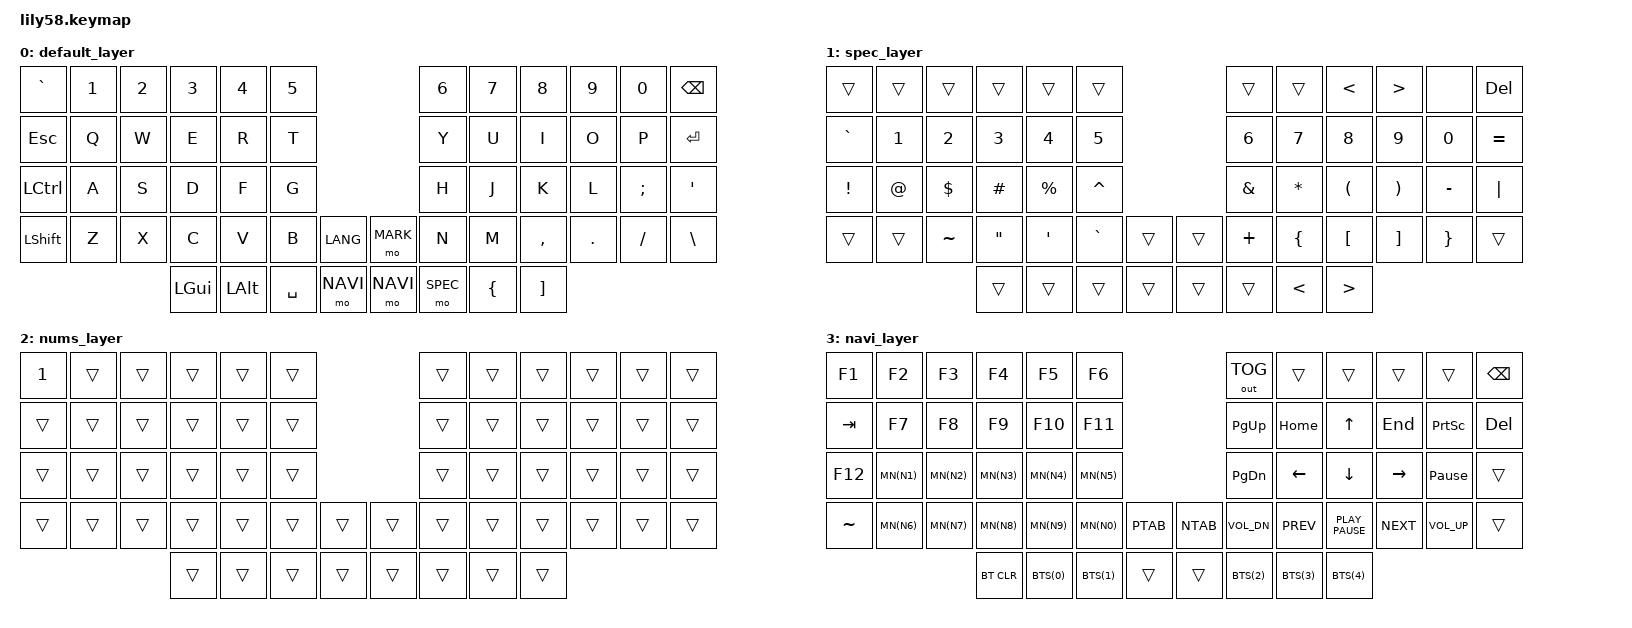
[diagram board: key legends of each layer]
/*
 * Copyright (c) 2020 The ZMK Contributors
 *
 * SPDX-License-Identifier: MIT
 */

#include <behaviors.dtsi>
#include <dt-bindings/zmk/keys.h>
#include <dt-bindings/zmk/bt.h>
#include <dt-bindings/zmk/outputs.h>
#include <dt-bindings/zmk/ext_power.h>

#define SPEC 1
#define NUMS 2
#define NAVI 3
#define MARK LC(SPACE)
#define BTS(n) &bt BT_SEL n
#define LANG CLCK
#define MN(n) &kp LG n
#define NTAB LC(TAB)
#define PTAB LC(LS(TAB))

/ {
	keymap {
		compatible = "zmk,keymap";

		default_layer {
// ---------------------------------------------------------------------------------------------------------
// |   `    |  1  |  2  |  3  |  4  |   5   |                    |   6   |   7   |  8  |  9  |  0  | BKSPC |
// |  ESC   |  Q  |  W  |  E  |  R  |   T   |                    |   Y   |   U   |  I  |  O  |  P  | ENTER |
// |  CTRL  |  A  |  S  |  D  |  F  |   G   |                    |   H   |   J   |  K  |  L  |  ;  |   '   |
// |  SHIFT |  Z  |  X  |  C  |  V  |   B   |  LANG  |  | MARK   |   N   |   M   |  ,  |  .  |  /  |   \   |
//                      | GUI | ALT |  SPC  |  NAVI  |  | NAVI   |  SPEC |   [   |  ]  |         
			bindings = <
&kp GRAVE &kp N1 &kp N2 &kp N3   &kp N4   &kp N5                          &kp N6    &kp N7    &kp N8    &kp N9  &kp N0    &kp BSPC
&kp ESC   &kp Q  &kp W  &kp E    &kp R    &kp T                           &kp Y     &kp U     &kp I     &kp O   &kp P     &kp ENTER
&kp LCTRL &kp A  &kp S  &kp D    &kp F    &kp G                           &kp H     &kp J     &kp K     &kp L   &kp SEMI  &kp SQT
&kp LSHFT &kp Z  &kp X  &kp C    &kp V    &kp B     &kp LANG   &mo MARK   &kp N     &kp M     &kp COMMA &kp DOT &kp SLASH &kp BACKSLASH
                        &kp LGUI &kp LALT &kp SPACE &mo NAVI   &mo NAVI   &mo SPEC  &kp LBRC  &kp RBKT
			>;
		};

		spec_layer {
// ----------------------------------------------------------------------------------------------------
// |     |     |     |     |     |       |                    |       |       |  <  |  >  |     | DEL |
// |  `  |  1  |  2  |  3  |  4  |   5   |                    |   6   |   7   |  8  |  9  |  0  |  =  |
// |  !  |  @  |  $  |  #  |  %  |   ^   |                    |   &   |   *   |  (  |  )  |  -  |  |  |
// |     |     |  ~  |  "  |  '  |   `   |        |  |        |   +   |   {   |  [  |  ]  |  }  |     |
//                   |     |     |       |        |  |        |       |   <   |  >  |
			bindings = <
&trans    &trans      &trans     &trans     &trans    &trans                        &trans    &trans     &kp LT    &kp GT    &none      &kp DEL
&kp GRAVE &kp N1      &kp N2     &kp N3     &kp N4    &kp N5                        &kp N6    &kp N7     &kp N8    &kp N9    &kp N0     &kp EQUAL
&kp EXCL  &kp AT      &kp DOLLAR &kp HASH   &kp PRCNT &kp CARET                     &kp AMPS  &kp ASTRK  &kp LPAR  &kp RPAR  &kp MINUS  &kp PIPE
&trans    &trans      &kp TILDE  &kp DQT    &kp SQT   &kp GRAVE   &trans  &trans    &kp PLUS  &kp LBRC   &kp LBKT  &kp RBKT  &kp RBRC   &trans
                                 &trans     &trans    &trans      &trans  &trans    &trans    &kp LT     &kp GT
			>;
		};

		nums_layer {
// ----------------------------------------------------------------------------------------------------
// |     |     |     |     |     |       |                    |       |       |     |     |     |     |
// |     |     |     |     |     |       |                    |       |       |     |     |     |     |
// |     |     |     |     |     |       |                    |       |       |     |     |     |     |
// |     |     |     |     |     |       |        |  |        |       |       |     |     |     |     |
//                   |     |     |       |        |  |        |       |       |     |
			bindings = <
&kp N1 &trans &trans &trans   &trans   &trans                       &trans     &trans   &trans     &trans  &trans    &trans
&trans &trans &trans &trans   &trans   &trans                       &trans     &trans   &trans     &trans  &trans    &trans
&trans &trans &trans &trans   &trans   &trans                       &trans     &trans   &trans     &trans  &trans    &trans
&trans &trans &trans &trans   &trans   &trans   &trans    &trans    &trans     &trans   &trans     &trans  &trans    &trans
                     &trans   &trans   &trans   &trans    &trans    &trans     &trans   &trans
			>;
		};

		navi_layer {
// ----------------------------------------------------------------------------------------------------
// | F1  | F2   | F3  | F4  | F5  |  F6   |                    | OUT_T |       |      |     |       | BSPC |
// | TAB | F7   | F8  | F9  | F10 |  F11  |                    | PGUP  | HOME  |  UP  | END | PSCR  | DEL  |
// | F12 |META+1|     |     |     |       |                    | PGDN  | LEFT  | DOWN |RIGHT| PAUSE |      |
// |TILDE|      |     |     |     |META+0 |  PTAB  |  |  NTAB  | VOLDN | PREV  |  PP  | NEXT|VOLUP  |      |
//                    |     |     |       |        |  |        |       |       |      |
			bindings = <
 
&kp F1    &kp F2 &kp F3 &kp F4       &kp F5        &kp F6                           &out OUT_TOG  &trans        &trans            &trans           &trans            &kp BSPC
&kp TAB   &kp F7 &kp F8 &kp F9       &kp F10       &kp F11                          &kp PG_UP     &kp HOME      &kp UP            &kp END          &kp PSCRN         &kp DEL
&kp F12   MN(N1) MN(N2) MN(N3)       MN(N4)        MN(N5)                           &kp PG_DN     &kp LEFT      &kp DOWN          &kp RIGHT        &kp PAUSE_BREAK   &trans
&kp TILDE MN(N6) MN(N7) MN(N8)       MN(N9)        MN(N0)      &kp PTAB  &kp NTAB   &kp C_VOL_DN  &kp K_PREV    &kp K_PLAY_PAUSE  &kp K_NEXT       &kp C_VOL_UP      &trans
                        &bt BT_CLR   BTS(0)        BTS(1)      &trans    &trans     BTS(2)        BTS(3)        BTS(4)
			>;
		};
  };
};
